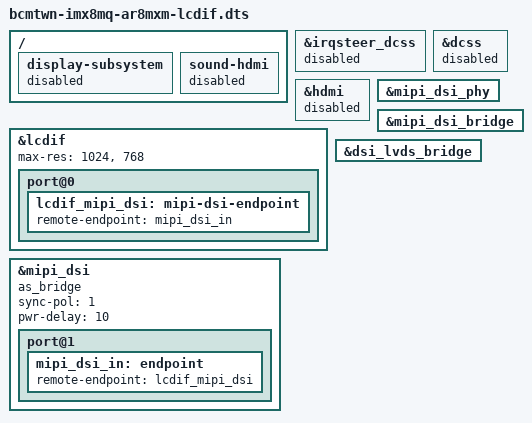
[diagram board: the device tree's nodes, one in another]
/*
 */

#include "bcmtwn-imx8mq-ar8mxm.dts"

/ {
	display-subsystem {
		status = "disabled";
	};

	sound-hdmi {
		status = "disabled";
	};
};

&irqsteer_dcss {
	status = "disabled";
};

&dcss {
	status = "disabled";
};

&hdmi {
	status = "disabled";
};

&lcdif {
	status = "okay";
	max-res = <1024>, <768>;

	port@0 {
		lcdif_mipi_dsi: mipi-dsi-endpoint {
			remote-endpoint = <&mipi_dsi_in>;
		};
	};
};

&mipi_dsi_phy {
	status = "okay";
};

&mipi_dsi {
	status = "okay";
	as_bridge;
	sync-pol = <1>;
	pwr-delay = <10>;

	port@1 {
		mipi_dsi_in: endpoint {
			remote-endpoint = <&lcdif_mipi_dsi>;
		};
	};
};

&mipi_dsi_bridge {
	status = "okay";
};

&dsi_lvds_bridge {
	status = "okay";
};
